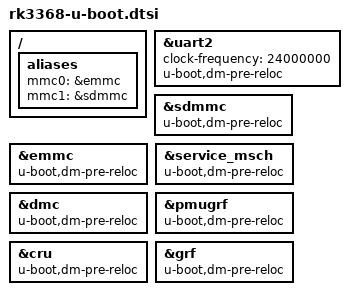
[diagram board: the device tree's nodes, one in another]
/*
 * (C) Copyright 2018 Rockchip Electronics Co., Ltd
 *
 * SPDX-License-Identifier:     GPL-2.0+
 */

/ {
	aliases {
		mmc0 = &emmc;
		mmc1 = &sdmmc;
	};
};

&uart2 {
	clock-frequency = <24000000>;
	u-boot,dm-pre-reloc;
};

&sdmmc {
	u-boot,dm-pre-reloc;
};

&emmc {
	u-boot,dm-pre-reloc;
	status = "okay";
};

&service_msch {
	u-boot,dm-pre-reloc;
};

&dmc {
	u-boot,dm-pre-reloc;
};

&pmugrf {
	u-boot,dm-pre-reloc;
};

&cru {
	u-boot,dm-pre-reloc;
};

&grf {
	u-boot,dm-pre-reloc;
};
